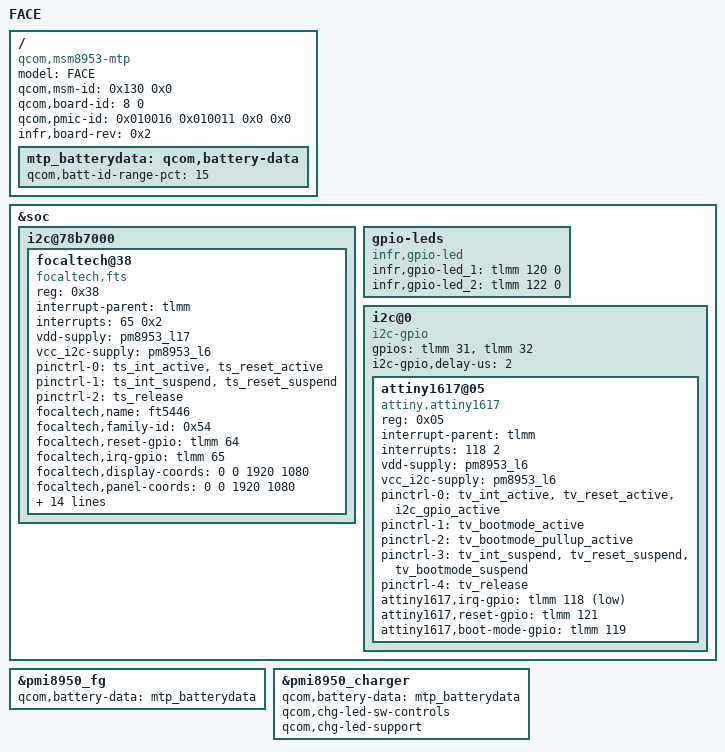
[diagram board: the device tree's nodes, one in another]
/*
 * Copyright (c) 2015-2017, The Linux Foundation. All rights reserved.
 *
 * This program is free software; you can redistribute it and/or modify
 * it under the terms of the GNU General Public License version 2 and
 * only version 2 as published by the Free Software Foundation.
 *
 * This program is distributed in the hope that it will be useful,
 * but WITHOUT ANY WARRANTY; without even the implied warranty of
 * MERCHANTABILITY or FITNESS FOR A PARTICULAR PURPOSE.  See the
 * GNU General Public License for more details.
 */

/dts-v1/;

#include "msm8953.dtsi"
#include "msm-pmi8950.dtsi"
#include "msm8953-mtp.dtsi"
#include "msm8953-pmi8950.dtsi"
#include "msm8953-camera-sensor-mtp.dtsi"

/ {
	model = "FACE";
	compatible = "qcom,msm8953-mtp", "qcom,msm8953", "qcom,mtp";
	qcom,msm-id = <0x130 0x0>;
//	qcom,pmic-id = <0x1000b 0x0 0x0 0x0>;
	qcom,board-id= <8 0>;
	qcom,pmic-id = <0x010016 0x010011 0x0 0x0>;
	infr,board-rev = <0x2>;
};

&soc {
//	i2c@78b6000 { /* BLSP1 QUP2 */
	i2c@78b7000 {
		focaltech@38 {
			compatible = "focaltech,fts";
			reg = <0x38>;
			interrupt-parent = <&tlmm>;
			interrupts = <65 0x2>;
			vdd-supply = <&pm8953_l17>;
			vcc_i2c-supply = <&pm8953_l6>;
			// pins used by touchscreen
			pinctrl-names = "pmx_ts_active","pmx_ts_suspend",
							"pmx_ts_release";
//							"pmx_ts_release","ts_ff";
			pinctrl-0 = <&ts_int_active &ts_reset_active>;
			pinctrl-1 = <&ts_int_suspend &ts_reset_suspend>;
			pinctrl-2 = <&ts_release>;
//			pinctrl-3 = <&ts_ff>;
			focaltech,name = "ft5446";
			focaltech,family-id = <0x54>;
			focaltech,reset-gpio = <&tlmm 64 0x0>;
			focaltech,irq-gpio = <&tlmm 65 0x2008>;
			focaltech,display-coords = <0 0 1920 1080>;
			focaltech,panel-coords = <0 0 1920 1080>;
			focaltech,no-force-update;
			focaltech,i2c-pull-up;
			focaltech,group-id = <1>;
			focaltech,hard-reset-delay-ms = <20>;
			focaltech,soft-reset-delay-ms = <200>;
			focaltech,num-max-touches = <10>;
			focaltech,fw-delay-aa-ms = <2>;
			focaltech,fw-delay-55-ms = <2>;
			focaltech,fw-upgrade-id1 = <0x54>;
			focaltech,fw-upgrade-id2 = <0x2c>;
			focaltech,fw-delay-readid-ms = <10>;
			focaltech,fw-delay-era-flsh-ms = <2000>;
			focaltech,fw-auto-cal;
			focaltech,resume-in-workqueue;
			//focaltech,fw-name = "FT5446_5.5inch_0x02_20170711_all.bin";
		};
	};
		gpio-leds {
			compatible = "infr,gpio-led";
			status = "okay";
			//pinctrl-names = "default";
			//pinctrl-0 = <&gpio_led_off>;
			infr,gpio-led_1 = <&tlmm 120 0>;
			infr,gpio-led_2 = <&tlmm 122 0>; 
			
		};

	i2c@0 { 
		compatible = "i2c-gpio";
		gpios = <&tlmm 31 0 /* sda */ 
				&tlmm 32 0 /* scl */ >; 
		//i2c-gpio,sda-open-drain;
		//i2c-gpio,scl-open-drain;
		i2c-gpio,delay-us = <2>;	/* ~200 kHz */
		#address-cells = <1>;
		#size-cells = <0>;
		attiny1617@05 {
			compatible = "attiny,attiny1617";
			reg = <0x05>;
			interrupt-parent = <&tlmm>;
			interrupts = <118 2>;
			vdd-supply = <&pm8953_l6>;
			vcc_i2c-supply = <&pm8953_l6>;
			pinctrl-names = "pmx_tv_active","pm_tv_boot_active","pmx_tv_bootmode_pullup_active","pmx_tv_suspend","pmx_tv_release";
			pinctrl-0 = <&tv_int_active &tv_reset_active &i2c_gpio_active>;
			pinctrl-1 = <&tv_bootmode_active>;
			pinctrl-2 = <&tv_bootmode_pullup_active>;
			pinctrl-3 = <&tv_int_suspend &tv_reset_suspend &tv_bootmode_suspend>;
			pinctrl-4 = <&tv_release>;
			attiny1617,irq-gpio = <&tlmm 118 0x03>;
			attiny1617,reset-gpio = <&tlmm 121 0x00>;
			attiny1617,boot-mode-gpio = <&tlmm 119 0x00>;
		};
	}; 
};

/{
	mtp_batterydata: qcom,battery-data {
		qcom,batt-id-range-pct = <15>;
		#include "batterydata_MarkT_IFS200N_3000mAh.dtsi"
	};
};

&pmi8950_fg {
	qcom,battery-data = <&mtp_batterydata>;
};

&pmi8950_charger {
	qcom,battery-data = <&mtp_batterydata>;
	qcom,chg-led-sw-controls;
	qcom,chg-led-support;
//	qcom,external-typec;
//	qcom,typec-psy-name = "typec";
};
